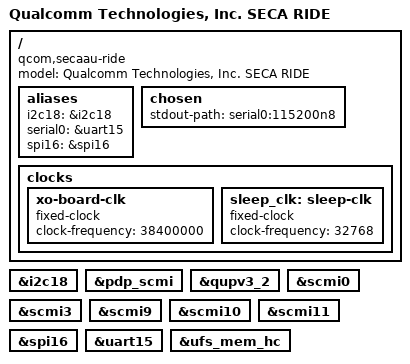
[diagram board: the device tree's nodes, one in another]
// SPDX-License-Identifier: BSD-3-Clause
/*
 * Copyright (c) Qualcomm Technologies, Inc. and/or its subsidiaries.
 */

/dts-v1/;

#include "seca-gearvm.dtsi"

/ {
	model = "Qualcomm Technologies, Inc. SECA RIDE";
	compatible = "qcom,secaau-ride", "qcom,seca";

	aliases {
		i2c18 = &i2c18;
		serial0 = &uart15;
		spi16 = &spi16;
	};

	chosen {
		stdout-path = "serial0:115200n8";
	};

	clocks {
		xo-board-clk {
			compatible = "fixed-clock";
			clock-frequency = <38400000>;
			#clock-cells = <0>;
		};

		sleep_clk: sleep-clk {
			compatible = "fixed-clock";
			clock-frequency = <32768>;
			#clock-cells = <0>;
		};
	};
};

&i2c18 {
	status = "okay";
};

&pdp_scmi {
	status = "okay";
};

&qupv3_2 {
	status = "okay";
};

&scmi0 {
	status = "okay";
};

&scmi3 {
	status = "okay";
};

&scmi9 {
	status = "okay";
};

&scmi10 {
	status = "okay";
};

&scmi11 {
	status = "okay";
};

&spi16 {
	status = "okay";
};

&uart15 {
	status = "okay";
};

&ufs_mem_hc {
	status = "okay";
};
